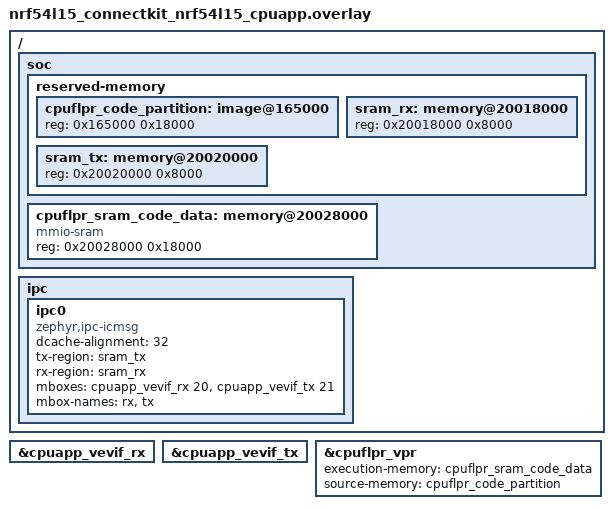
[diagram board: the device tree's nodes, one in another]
/ {
	soc {
		reserved-memory {
			#address-cells = <1>;
			#size-cells = <1>;

			cpuflpr_code_partition: image@165000 {
				reg = <0x165000 0x18000>;
			};

			sram_rx: memory@20018000 {
				reg = <0x20018000 0x8000>;
			};

			sram_tx: memory@20020000 {
				reg = <0x20020000 0x8000>;
			};
		};

		cpuflpr_sram_code_data: memory@20028000 {
			compatible = "mmio-sram";
			reg = <0x20028000 0x18000>;
			#address-cells = <1>;
			#size-cells = <1>;
			ranges = <0x0 0x20028000 0x18000>;
		};
	};

	ipc {
		ipc0: ipc0 {
			compatible = "zephyr,ipc-icmsg";
			dcache-alignment = <32>;
			tx-region = <&sram_tx>;
			rx-region = <&sram_rx>;
			mboxes = <&cpuapp_vevif_rx 20>, <&cpuapp_vevif_tx 21>;
			mbox-names = "rx", "tx";
			status = "okay";
		};
	};
};

&cpuapp_vevif_rx {
	status = "okay";
};

&cpuapp_vevif_tx {
	status = "okay";
};

&cpuflpr_vpr {
	execution-memory = <&cpuflpr_sram_code_data>;
	source-memory = <&cpuflpr_code_partition>;
	status = "okay";
};
